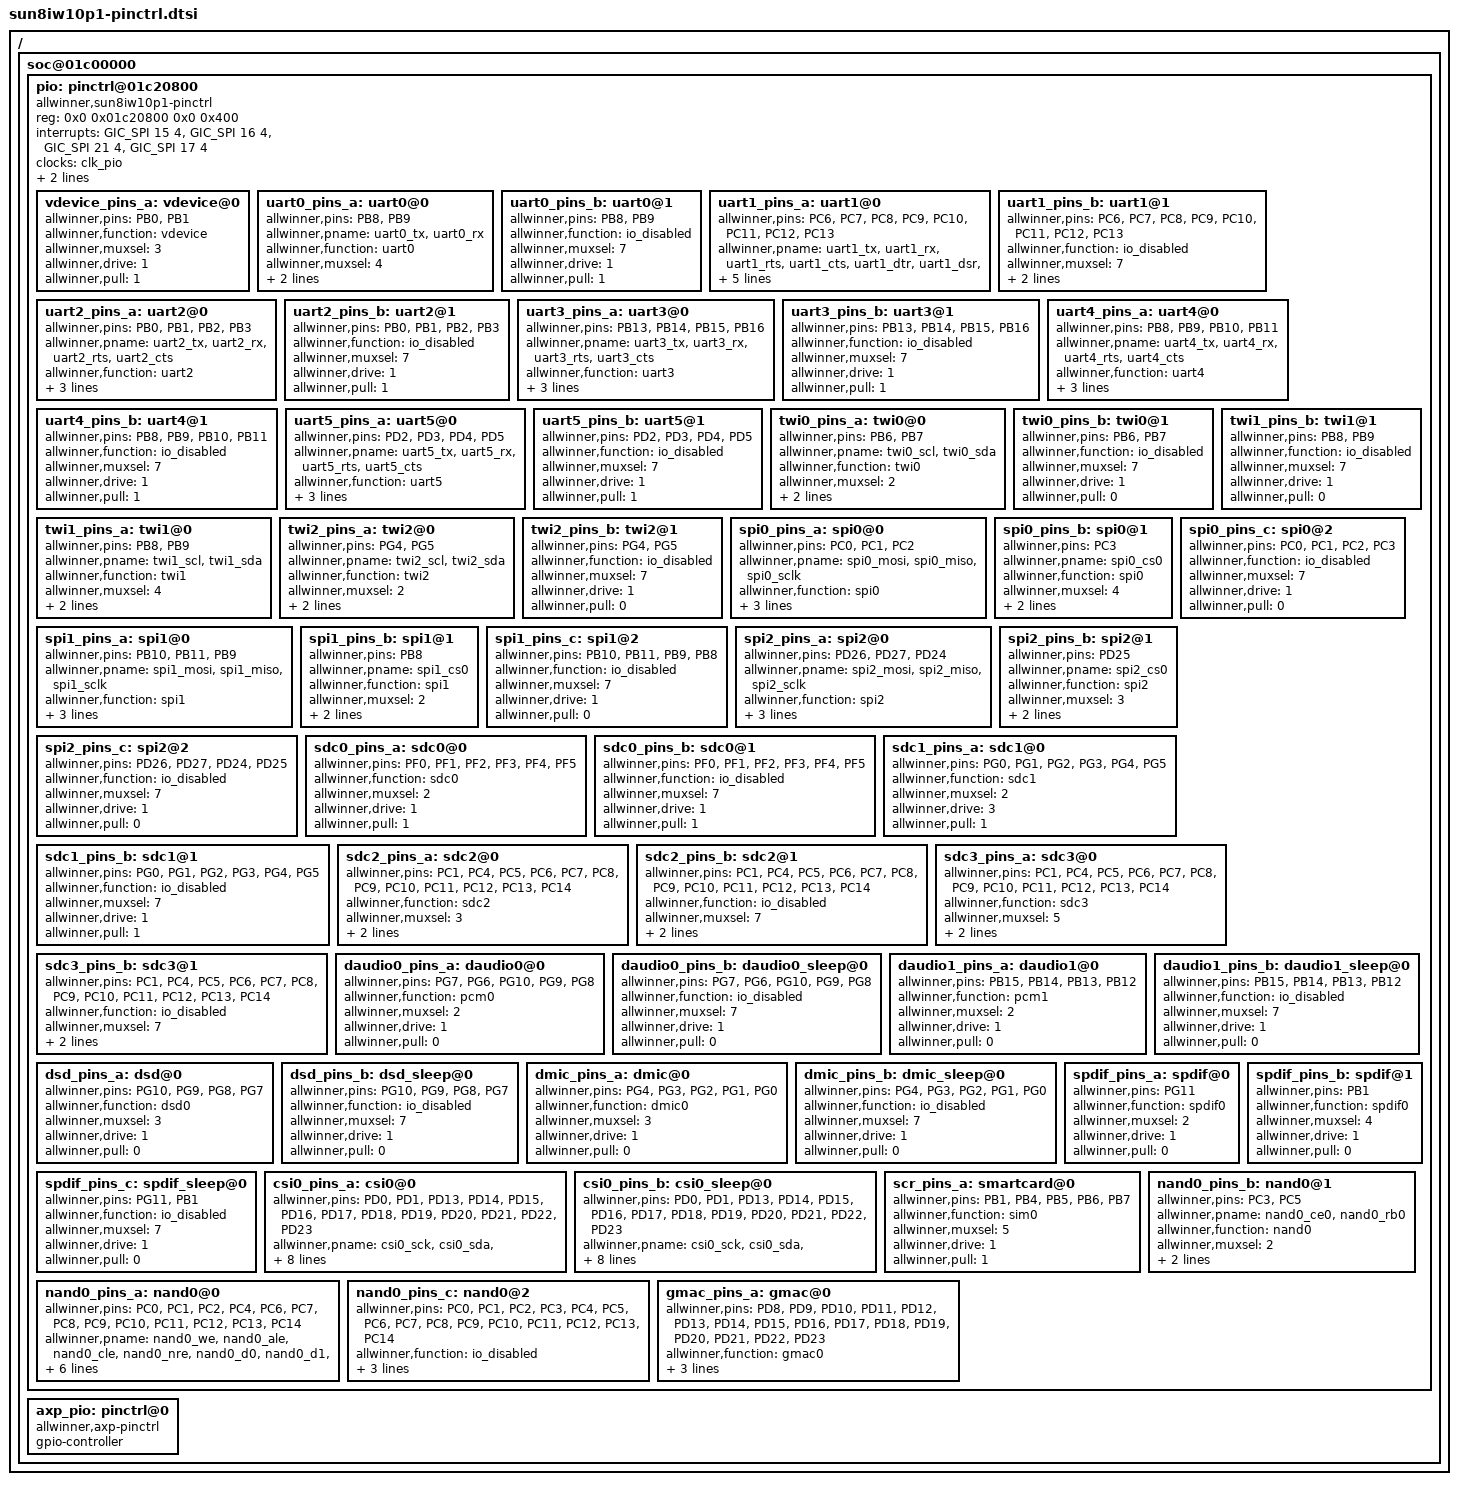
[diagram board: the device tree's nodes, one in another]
/*
 * Allwinner 1689 pin config info.
 */

/ {
	soc@01c00000{
		pio: pinctrl@01c20800 {
			compatible = "allwinner,sun8iw10p1-pinctrl";
			reg = <0x0 0x01c20800 0x0 0x400>;
			interrupts = <GIC_SPI 15 4>,
				     <GIC_SPI 16 4>,
				     <GIC_SPI 21 4>,
				     <GIC_SPI 17 4>;
			device_type = "pio";
			clocks = <&clk_pio>;
			gpio-controller;
			interrupt-controller;
			#interrupt-cells = <2>;
			#size-cells = <0>;
			#gpio-cells = <6>;

			vdevice_pins_a: vdevice@0 {
				allwinner,pins = "PB0", "PB1";
				allwinner,function = "vdevice";
				allwinner,muxsel = <3>;
				allwinner,drive = <1>;
				allwinner,pull = <1>;
			};

			uart0_pins_a: uart0@0 {
				allwinner,pins = "PB8", "PB9";
				allwinner,pname = "uart0_tx", "uart0_rx";
				allwinner,function = "uart0";
				allwinner,muxsel = <4>;
				allwinner,drive = <1>;
				allwinner,pull = <1>;
			};

			uart0_pins_b: uart0@1 {
				allwinner,pins = "PB8", "PB9";
				allwinner,function = "io_disabled";
				allwinner,muxsel = <7>;
				allwinner,drive = <1>;
				allwinner,pull = <1>;
			};

			uart1_pins_a: uart1@0 {
				allwinner,pins = "PC6", "PC7", "PC8", "PC9", "PC10", "PC11", "PC12", "PC13";
				allwinner,pname = "uart1_tx", "uart1_rx", "uart1_rts", "uart1_cts", "uart1_dtr", "uart1_dsr", "uart1_dcd", "uart1_ring";
				allwinner,function = "uart1";
				allwinner,muxsel = <4>;
				allwinner,drive = <1>;
				allwinner,pull = <1>;
			};

			uart1_pins_b: uart1@1 {
				allwinner,pins = "PC6", "PC7", "PC8", "PC9", "PC10", "PC11", "PC12", "PC13";
				allwinner,function = "io_disabled";
				allwinner,muxsel = <7>;
				allwinner,drive = <1>;
				allwinner,pull = <1>;
			};

			uart2_pins_a: uart2@0 {
				allwinner,pins = "PB0", "PB1", "PB2", "PB3";
				allwinner,pname = "uart2_tx", "uart2_rx", "uart2_rts", "uart2_cts";
				allwinner,function = "uart2";
				allwinner,muxsel = <2>;
				allwinner,drive = <1>;
				allwinner,pull = <1>;
			};

			uart2_pins_b: uart2@1 {
				allwinner,pins = "PB0", "PB1", "PB2", "PB3";
				allwinner,function = "io_disabled";
				allwinner,muxsel = <7>;
				allwinner,drive = <1>;
				allwinner,pull = <1>;
			};

			uart3_pins_a: uart3@0 {
				allwinner,pins = "PB13", "PB14", "PB15", "PB16";
				allwinner,pname = "uart3_tx", "uart3_rx", "uart3_rts", "uart3_cts";
				allwinner,function = "uart3";
				allwinner,muxsel = <5>;
				allwinner,drive = <1>;
				allwinner,pull = <1>;
			};

			uart3_pins_b: uart3@1 {
				allwinner,pins = "PB13", "PB14", "PB15", "PB16";
				allwinner,function = "io_disabled";
				allwinner,muxsel = <7>;
				allwinner,drive = <1>;
				allwinner,pull = <1>;
			};

			uart4_pins_a: uart4@0 {
				allwinner,pins = "PB8", "PB9", "PB10", "PB11";
				allwinner,pname = "uart4_tx", "uart4_rx", "uart4_rts", "uart4_cts";
				allwinner,function = "uart4";
				allwinner,muxsel = <3>;
				allwinner,drive = <1>;
				allwinner,pull = <1>;
			};

			uart4_pins_b: uart4@1 {
				allwinner,pins = "PB8", "PB9", "PB10", "PB11";
				allwinner,function = "io_disabled";
				allwinner,muxsel = <7>;
				allwinner,drive = <1>;
				allwinner,pull = <1>;
			};

			uart5_pins_a: uart5@0 {
				allwinner,pins = "PD2", "PD3", "PD4", "PD5";
				allwinner,pname = "uart5_tx", "uart5_rx", "uart5_rts", "uart5_cts";
				allwinner,function = "uart5";
				allwinner,muxsel = <3>;
				allwinner,drive = <1>;
				allwinner,pull = <1>;
			};

			uart5_pins_b: uart5@1 {
				allwinner,pins = "PD2", "PD3", "PD4", "PD5";
				allwinner,function = "io_disabled";
				allwinner,muxsel = <7>;
				allwinner,drive = <1>;
				allwinner,pull = <1>;
			};

			twi0_pins_a: twi0@0 {
				allwinner,pins = "PB6", "PB7";
				allwinner,pname = "twi0_scl", "twi0_sda";
				allwinner,function = "twi0";
				allwinner,muxsel = <2>;
				allwinner,drive = <1>;
				allwinner,pull = <0>;
			};

			twi0_pins_b: twi0@1 {
				allwinner,pins = "PB6", "PB7";
				allwinner,function = "io_disabled";
				allwinner,muxsel = <7>;
				allwinner,drive = <1>;
				allwinner,pull = <0>;
			};

			twi1_pins_a: twi1@0 {
				allwinner,pins = "PB8", "PB9";
				allwinner,pname = "twi1_scl", "twi1_sda";
				allwinner,function = "twi1";
				allwinner,muxsel = <4>;
				allwinner,drive = <1>;
				allwinner,pull = <0>;
			};

			twi1_pins_b: twi1@1 {
				allwinner,pins = "PB8", "PB9";
				allwinner,function = "io_disabled";
				allwinner,muxsel = <7>;
				allwinner,drive = <1>;
				allwinner,pull = <0>;
			};

			twi2_pins_a: twi2@0 {
				allwinner,pins = "PG4", "PG5";
				allwinner,pname = "twi2_scl", "twi2_sda";
				allwinner,function = "twi2";
				allwinner,muxsel = <2>;
				allwinner,drive = <1>;
				allwinner,pull = <0>;
			};

			twi2_pins_b: twi2@1 {
				allwinner,pins = "PG4", "PG5";
				allwinner,function = "io_disabled";
				allwinner,muxsel = <7>;
				allwinner,drive = <1>;
				allwinner,pull = <0>;
			};

			spi0_pins_a: spi0@0 {
				allwinner,pins = "PC0", "PC1", "PC2";
				allwinner,pname = "spi0_mosi", "spi0_miso", "spi0_sclk";
				allwinner,function = "spi0";
				allwinner,muxsel = <4>;
				allwinner,drive = <1>;
				allwinner,pull = <0>;
			};

			spi0_pins_b: spi0@1 {
				allwinner,pins = "PC3";
				allwinner,pname = "spi0_cs0";
				allwinner,function = "spi0";
				allwinner,muxsel = <4>;
				allwinner,drive = <1>;
				allwinner,pull = <1>; 	// only CS should be pulled up
			};

			spi0_pins_c: spi0@2 {
				allwinner,pins = "PC0", "PC1", "PC2", "PC3";
				allwinner,function = "io_disabled";
				allwinner,muxsel = <7>;
				allwinner,drive = <1>;
				allwinner,pull = <0>;
			};

			spi1_pins_a: spi1@0 {
				allwinner,pins = "PB10", "PB11", "PB9";
				allwinner,pname = "spi1_mosi", "spi1_miso", "spi1_sclk";
				allwinner,function = "spi1";
				allwinner,muxsel = <2>;
				allwinner,drive = <1>;
				allwinner,pull = <0>;
			};

			spi1_pins_b: spi1@1 {
				allwinner,pins = "PB8";
				allwinner,pname = "spi1_cs0";
				allwinner,function = "spi1";
				allwinner,muxsel = <2>;
				allwinner,drive = <1>;
				allwinner,pull = <1>; 	// only CS should be pulled up
			};

			spi1_pins_c: spi1@2 {
				allwinner,pins = "PB10", "PB11", "PB9", "PB8";
				allwinner,function = "io_disabled";
				allwinner,muxsel = <7>;
				allwinner,drive = <1>;
				allwinner,pull = <0>;
			};

			spi2_pins_a: spi2@0 {
				allwinner,pins = "PD26", "PD27", "PD24";
				allwinner,pname = "spi2_mosi", "spi2_miso", "spi2_sclk";
				allwinner,function = "spi2";
				allwinner,muxsel = <3>;
				allwinner,drive = <1>;
				allwinner,pull = <0>;
			};

			spi2_pins_b: spi2@1 {
				allwinner,pins = "PD25";
				allwinner,pname = "spi2_cs0";
				allwinner,function = "spi2";
				allwinner,muxsel = <3>;
				allwinner,drive = <1>;
				allwinner,pull = <1>;   // only CS should be pulled up
			};

			spi2_pins_c: spi2@2 {
				allwinner,pins = "PD26", "PD27", "PD24", "PD25";
				allwinner,function = "io_disabled";
				allwinner,muxsel = <7>;
				allwinner,drive = <1>;
				allwinner,pull = <0>;
			};

			sdc0_pins_a: sdc0@0 {
				allwinner,pins = "PF0", "PF1", "PF2", "PF3","PF4","PF5";
				allwinner,function = "sdc0";
				allwinner,muxsel = <2>;
				allwinner,drive = <1>;
				allwinner,pull = <1>;
			};

			sdc0_pins_b: sdc0@1 {
				allwinner,pins = "PF0", "PF1", "PF2", "PF3","PF4","PF5";
				allwinner,function = "io_disabled";
				allwinner,muxsel = <7>;
				allwinner,drive = <1>;
				allwinner,pull = <1>;
			};

			sdc1_pins_a: sdc1@0 {
				allwinner,pins = "PG0", "PG1", "PG2", "PG3","PG4","PG5";
				allwinner,function = "sdc1";
				allwinner,muxsel = <2>;
				allwinner,drive = <3>;
				allwinner,pull = <1>;
			};

			sdc1_pins_b: sdc1@1 {
				allwinner,pins = "PG0", "PG1", "PG2", "PG3","PG4","PG5";
				allwinner,function = "io_disabled";
				allwinner,muxsel = <7>;
				allwinner,drive = <1>;
				allwinner,pull = <1>;
			};

			sdc2_pins_a: sdc2@0 {
				allwinner,pins = "PC1","PC4", "PC5", "PC6", "PC7","PC8","PC9","PC10","PC11","PC12","PC13","PC14";
				allwinner,function = "sdc2";
				allwinner,muxsel = <3>;
				allwinner,drive = <2>;
				allwinner,pull = <1>;
			};

			sdc2_pins_b: sdc2@1 {
				allwinner,pins = "PC1","PC4", "PC5", "PC6", "PC7","PC8","PC9","PC10","PC11","PC12","PC13","PC14";
				allwinner,function = "io_disabled";
				allwinner,muxsel = <7>;
				allwinner,drive = <1>;
				allwinner,pull = <1>;
			};

			sdc3_pins_a: sdc3@0 {
				allwinner,pins = "PC1","PC4", "PC5", "PC6", "PC7","PC8","PC9","PC10","PC11","PC12","PC13","PC14";
				allwinner,function = "sdc3";
				allwinner,muxsel = <5>;
				allwinner,drive = <2>;
				allwinner,pull = <1>;
			};

			sdc3_pins_b: sdc3@1 {
				allwinner,pins = "PC1","PC4", "PC5", "PC6", "PC7","PC8","PC9","PC10","PC11","PC12","PC13","PC14";
				allwinner,function = "io_disabled";
				allwinner,muxsel = <7>;
				allwinner,drive = <1>;
				allwinner,pull = <1>;
			};


			daudio0_pins_a: daudio0@0 {
				allwinner,pins = "PG7", "PG6", "PG10", "PG9", "PG8";
				allwinner,function = "pcm0";
				allwinner,muxsel = <2>;
				allwinner,drive = <1>;
				allwinner,pull = <0>;
			};
			daudio0_pins_b: daudio0_sleep@0 {
				allwinner,pins = "PG7", "PG6", "PG10", "PG9", "PG8";
				allwinner,function = "io_disabled";
				allwinner,muxsel = <7>;
				allwinner,drive = <1>;
				allwinner,pull = <0>;
			};
			daudio1_pins_a: daudio1@0 {
				allwinner,pins = "PB15", "PB14", "PB13", "PB12";
				allwinner,function = "pcm1";
				allwinner,muxsel = <2>;
				allwinner,drive = <1>;
				allwinner,pull = <0>;
			};
			daudio1_pins_b: daudio1_sleep@0 {
				allwinner,pins = "PB15", "PB14", "PB13", "PB12";
				allwinner,function = "io_disabled";
				allwinner,muxsel = <7>;
				allwinner,drive = <1>;
				allwinner,pull = <0>;
			};
			dsd_pins_a: dsd@0 {
				allwinner,pins = "PG10", "PG9", "PG8", "PG7";
				allwinner,function = "dsd0";
				allwinner,muxsel = <3>;
				allwinner,drive = <1>;
				allwinner,pull = <0>;
			};
			dsd_pins_b: dsd_sleep@0 {
				allwinner,pins = "PG10", "PG9", "PG8", "PG7";
				allwinner,function = "io_disabled";
				allwinner,muxsel = <7>;
				allwinner,drive = <1>;
				allwinner,pull = <0>;
			};
			dmic_pins_a: dmic@0 {
				allwinner,pins = "PG4", "PG3", "PG2", "PG1", "PG0";
				allwinner,function = "dmic0";
				allwinner,muxsel = <3>;
				allwinner,drive = <1>;
				allwinner,pull = <0>;
			};
			dmic_pins_b: dmic_sleep@0 {
				allwinner,pins = "PG4", "PG3", "PG2", "PG1", "PG0";
				allwinner,function = "io_disabled";
				allwinner,muxsel = <7>;
				allwinner,drive = <1>;
				allwinner,pull = <0>;
			};
			spdif_pins_a: spdif@0 {
				allwinner,pins = "PG11";
				allwinner,function = "spdif0";
				allwinner,muxsel = <2>;
				allwinner,drive = <1>;
				allwinner,pull = <0>;
			};
			spdif_pins_b: spdif@1 {
				allwinner,pins = "PB1";
				allwinner,function = "spdif0";
				allwinner,muxsel = <4>;
				allwinner,drive = <1>;
				allwinner,pull = <0>;
			};
			spdif_pins_c: spdif_sleep@0 {
				allwinner,pins = "PG11", "PB1";/*ph8-spec*/
				allwinner,function = "io_disabled";
				allwinner,muxsel = <7>;
				allwinner,drive = <1>;
				allwinner,pull = <0>;
			};

			csi0_pins_a: csi0@0 {
				allwinner,pins = "PD0","PD1","PD13","PD14","PD15","PD16","PD17","PD18","PD19","PD20","PD21","PD22","PD23";
				allwinner,pname = "csi0_sck","csi0_sda","csi0_hsync","csi0_vsync","csi0_pck","csi0_d0","csi0_d1","csi0_d2",
								"csi0_d3","csi0_d4","csi0_d5","csi0_d6","csi0_d7";
				allwinner,function = "csi0";
				allwinner,muxsel = <4>;
				allwinner,drive = <1>;
				allwinner,pull = <0>;
				allwinner,data = <0>;
			};
			csi0_pins_b: csi0_sleep@0 {
				allwinner,pins = "PD0","PD1","PD13","PD14","PD15","PD16","PD17","PD18","PD19","PD20","PD21","PD22","PD23";
				allwinner,pname = "csi0_sck","csi0_sda","csi0_hsync","csi0_vsync","csi0_pck","csi0_d0","csi0_d1","csi0_d2",
								"csi0_d3","csi0_d4","csi0_d5","csi0_d6","csi0_d7";
				allwinner,function = "io_disabled";
				allwinner,muxsel = <7>;
				allwinner,drive = <1>;
				allwinner,pull = <0>;
				allwinner,data = <0>;
			};

			scr_pins_a: smartcard@0 {
				allwinner,pins = "PB1", "PB4", "PB5", "PB6","PB7";
				allwinner,function = "sim0";
				allwinner,muxsel = <5>;
				allwinner,drive = <1>;
				allwinner,pull = <1>;
			};

			nand0_pins_a: nand0@0 {
				allwinner,pins = "PC0",      "PC1",       "PC2",       "PC4",       "PC6",      "PC7",      "PC8",      "PC9",      "PC10",     "PC11",     "PC12",     "PC13",     "PC14";
				allwinner,pname= "nand0_we", "nand0_ale", "nand0_cle", "nand0_nre", "nand0_d0", "nand0_d1", "nand0_d2", "nand0_d3", "nand0_d4", "nand0_d5", "nand0_d6", "nand0_d7", "nand0_ndqs";
				allwinner,function = "nand0";
				allwinner,muxsel = <2>;
				allwinner,drive = <1>;
				allwinner,pull = <0>;
			};

			nand0_pins_b: nand0@1 {
				allwinner,pins = "PC3",       "PC5";
				allwinner,pname= "nand0_ce0", "nand0_rb0";
				allwinner,function = "nand0";
				allwinner,muxsel = <2>;
				allwinner,drive = <1>;
				allwinner,pull = <1>;// only RB&CE should be pulled up
			};

			nand0_pins_c: nand0@2 {
				allwinner,pins ="PC0", "PC1", "PC2", "PC3", "PC4", "PC5", "PC6", "PC7", "PC8", "PC9", "PC10", "PC11", "PC12", "PC13", "PC14";
				allwinner,function = "io_disabled";
				allwinner,muxsel = <7>;
				allwinner,drive = <1>;
				allwinner,pull = <0>;
			};

			gmac_pins_a: gmac@0 {
				allwinner,pins = "PD8", "PD9", "PD10", "PD11",
						"PD12", "PD13", "PD14", "PD15",
						"PD16", "PD17", "PD18", "PD19",
						"PD20", "PD21", "PD22", "PD23";
				allwinner,function = "gmac0";
				allwinner,muxsel = <4>;
				allwinner,drive = <3>;
				allwinner,pull = <0>;
			};
		};

		axp_pio: pinctrl@0 {
			compatible = "allwinner,axp-pinctrl";
			gpio-controller;
			#size-cells = <0>;
			#gpio-cells = <6>;
			device_type = "axp_pio";
		};
	};
};
